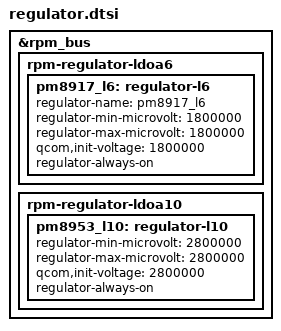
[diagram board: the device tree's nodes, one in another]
/* msm8917-regulator */

&rpm_bus {
       rpm-regulator-ldoa6 {
		status = "okay";
		pm8917_l6: regulator-l6 {
			regulator-name = "pm8917_l6";
			regulator-min-microvolt = <1800000>;
			regulator-max-microvolt = <1800000>;
			qcom,init-voltage = <1800000>;
			status = "okay";
			regulator-always-on;
		};
	}; 
};

/* msm8953-regulator */

&rpm_bus {
	rpm-regulator-ldoa10 {
		pm8953_l10: regulator-l10 {
			regulator-min-microvolt = <2800000>;
			regulator-max-microvolt = <2800000>;
			qcom,init-voltage = <2800000>;
			regulator-always-on;
		};
	};
};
